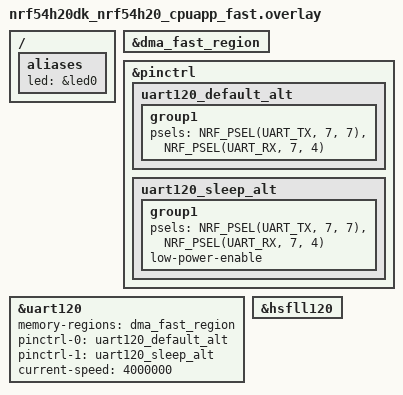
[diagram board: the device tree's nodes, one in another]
/*
 * Copyright (c) 2024 Nordic Semiconductor ASA
 *
 * SPDX-License-Identifier: LicenseRef-Nordic-5-Clause
 */

/ {
	aliases {
		led = &led0;
		/delete-property/ led1;
	};
};

/delete-node/ &led1;

&dma_fast_region {
	status = "okay";
};

/* UART device used for test
 * not the default UART assignment for the LD
 */
&pinctrl {
	uart120_default_alt: uart120_default_alt {
		group1 {
			psels = <NRF_PSEL(UART_TX, 7, 7)>,
				<NRF_PSEL(UART_RX, 7, 4)>;
		};
	};

	uart120_sleep_alt: uart120_sleep_alt {
		group1 {
			psels = <NRF_PSEL(UART_TX, 7, 7)>,
				<NRF_PSEL(UART_RX, 7, 4)>;
			low-power-enable;
		};
	};
};

dut: &uart120 {
	status = "okay";
	memory-regions = <&dma_fast_region>;
	pinctrl-0 = <&uart120_default_alt>;
	pinctrl-1 = <&uart120_sleep_alt>;
	pinctrl-names = "default", "sleep";
	current-speed = <4000000>;
};

&hsfll120 {
	status = "okay";
};
